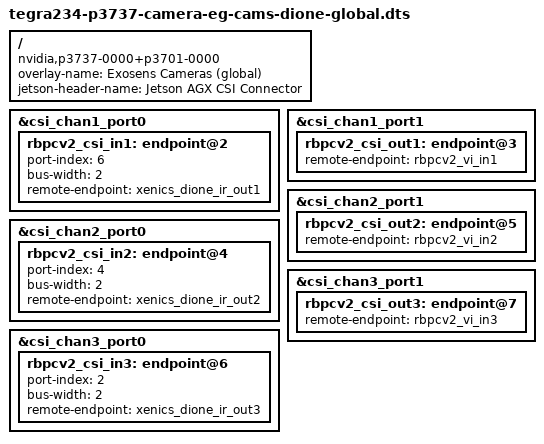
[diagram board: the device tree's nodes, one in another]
// SPDX-License-Identifier: GPL-2.0-only
// SPDX-FileCopyrightText: Copyright (c) 2023-2024, NVIDIA CORPORATION & AFFILIATES. All rights reserved.

/dts-v1/;
/plugin/;

#include "tegra234-p3737-camera-common-eg-cams-dione.dtsi"

/ {
	overlay-name = "Exosens Cameras (global)";
	jetson-header-name = "Jetson AGX CSI Connector";
	compatible = "nvidia,p3737-0000+p3701-0000", "nvidia,p3737-0000+p3701-0004", "nvidia,p3737-0000+p3701-0005";

	/*
	 * NVCSI channels 1-3: global endpoint numbering.
	 * Applied when no IMX219 nodes in /proc/device-tree (Auvidea 35.4.1, NVIDIA std).
	 */
	fragment@1 {
		target = <&csi_chan1_port0>;
		__overlay__ {
			rbpcv2_csi_in1: endpoint@2 {
				status = "okay";
				port-index = <6>;
				bus-width = <2>;
				remote-endpoint = <&xenics_dione_ir_out1>;
			};
		};
	};

	fragment@2 {
		target = <&csi_chan1_port1>;
		__overlay__ {
			rbpcv2_csi_out1: endpoint@3 {
				status = "okay";
				remote-endpoint = <&rbpcv2_vi_in1>;
			};
		};
	};

	fragment@3 {
		target = <&csi_chan2_port0>;
		__overlay__ {
			rbpcv2_csi_in2: endpoint@4 {
				status = "okay";
				port-index = <4>;
				bus-width = <2>;
				remote-endpoint = <&xenics_dione_ir_out2>;
			};
		};
	};

	fragment@4 {
		target = <&csi_chan2_port1>;
		__overlay__ {
			rbpcv2_csi_out2: endpoint@5 {
				status = "okay";
				remote-endpoint = <&rbpcv2_vi_in2>;
			};
		};
	};

	fragment@5 {
		target = <&csi_chan3_port0>;
		__overlay__ {
			rbpcv2_csi_in3: endpoint@6 {
				status = "okay";
				port-index = <2>;
				bus-width = <2>;
				remote-endpoint = <&xenics_dione_ir_out3>;
			};
		};
	};

	fragment@6 {
		target = <&csi_chan3_port1>;
		__overlay__ {
			rbpcv2_csi_out3: endpoint@7 {
				status = "okay";
				remote-endpoint = <&rbpcv2_vi_in3>;
			};
		};
	};
};
